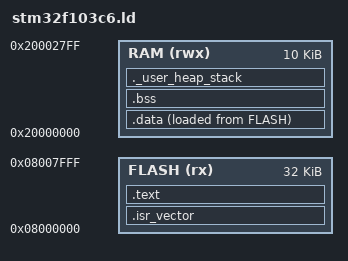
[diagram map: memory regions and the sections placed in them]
/*
 * Linker script for STM32F103C6T6
 *   Flash : 32 KB  @ 0x08000000
 *   RAM   : 10 KB  @ 0x20000000
 */

ENTRY(Reset_Handler)

MEMORY
{
    FLASH (rx)  : ORIGIN = 0x08000000, LENGTH = 32K
    RAM   (rwx) : ORIGIN = 0x20000000, LENGTH = 10K
}

_estack = ORIGIN(RAM) + LENGTH(RAM);   /* top of RAM = initial SP */

SECTIONS
{
    .isr_vector :
    {
        . = ALIGN(4);
        KEEP(*(.isr_vector))
        . = ALIGN(4);
    } > FLASH

    .text :
    {
        . = ALIGN(4);
        *(.text.Reset_Handler)
        *(.text)
        *(.text*)
        *(.rodata)
        *(.rodata*)
        . = ALIGN(4);
    } > FLASH

    /* Symbol used by Reset_Handler as the source address for .data init */
    _sidata = LOADADDR(.data);

    .data :
    {
        . = ALIGN(4);
        _sdata = .;
        *(.data)
        *(.data*)
        . = ALIGN(4);
        _edata = .;
    } > RAM AT> FLASH

    .bss :
    {
        . = ALIGN(4);
        _sbss = .;
        *(.bss)
        *(.bss*)
        *(COMMON)
        . = ALIGN(4);
        _ebss = .;
    } > RAM

    /* Reserve space for main stack + heap, catch RAM overflow at link time */
    ._user_heap_stack :
    {
        . = ALIGN(8);
        . = . + 0x400;   /* 1KB minimum headroom for stack/heap */
        . = ALIGN(8);
    } > RAM

    /DISCARD/ :
    {
        libc.a ( * )
        libm.a ( * )
        libgcc.a ( * )
    }
}
